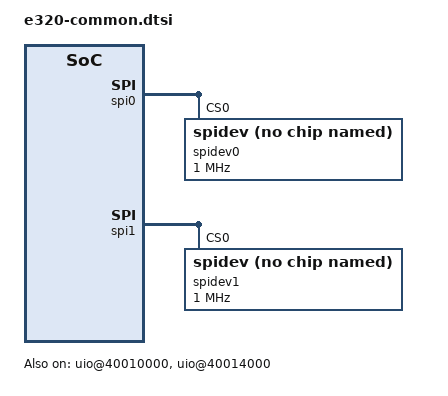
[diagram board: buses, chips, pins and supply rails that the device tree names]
/*
 * Copyright (c) 2018 National Instruments Corp
 *
 * SPDX-License-Identifier: GPL-2.0 OR X11
 */

fragment@2 {
	target = <&amba>;
	reg = <0x0002>;
	__overlay__ {
		#address-cells = <1>;
		#size-cells = <1>;
		uio@40010000 {
			compatible = "usrp-uio";
			reg = <0x40010000 0x2000>;
			reg-names = "mboard-regs";
			status = "okay";
		};

		uio@40014000 {
			compatible = "usrp-uio";
			reg = <0x40014000 0x4000>;
			reg-names = "dboard-regs";
			status = "okay";
		};
	};
};

fragment@5 {
	target = <&spi0>;
	reg = <0x0005>;
	__overlay__ {
		#address-cells = <1>;
		#size-cells = <0>;
		status = "okay";

		cs-gpios = <0>, <0>, <0>, <&gpio0 62 0>;

		spidev0: spidev@0 {
			compatible = "rohm,dh2228fv";
			reg = <0>;
			status = "okay";
			spi-max-frequency = <1000000>;
		};
	};
};

fragment@6 {
    target = <&spi1>;
	reg = <0x0006>;
	__overlay__ {
		#address-cells = <1>;
		#size-cells = <0>;
		status = "okay";

		cs-gpios = <0>, <0>, <0>, <&gpio0 63 0>;

		spidev1: spidev@0 {
			compatible = "rohm,dh2228fv";
			reg = <0>;
			status = "okay";
			spi-max-frequency = <1000000>;
		};
	};
};
